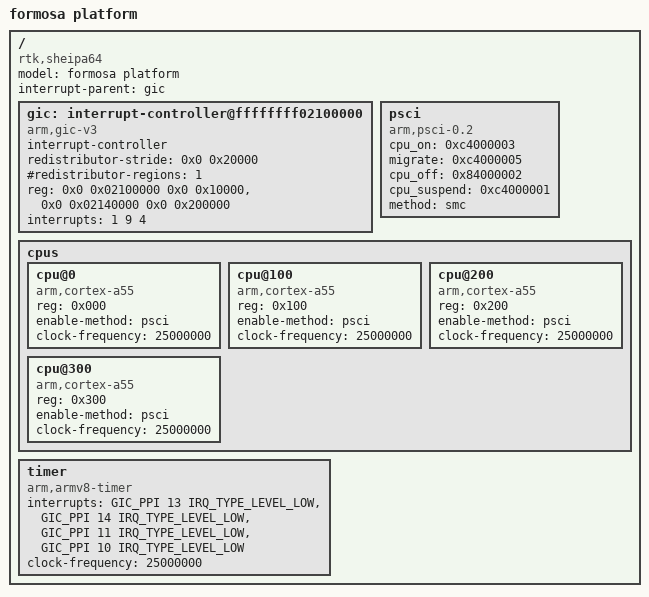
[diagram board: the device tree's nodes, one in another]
/*
 * Realtek Semiconductor Corp.
 *
 * Sheipa platform for AArch64
 *
 * Johnson Yu (jsonyu@realtek.com)
 * Jul. 20, 2017
 */

/dts-v1/;

#include <dt-bindings/interrupt-controller/arm-gic.h>
#include "sheipa64.dtsi"

/ {
	model = "formosa platform";
	compatible = "rtk,sheipa64", "rtk,formosa64";
	interrupt-parent = <&gic>;
	#address-cells = <2>;
	#size-cells = <2>;

        gic: interrupt-controller@ffffffff02100000 {
		compatible = "arm,gic-v3";
		#interrupt-cells = <3>;
		#address-cells = <2>;
		#size-cells = <2>;
		interrupt-controller;
		redistributor-stride = <0x0 0x20000>;
		#redistributor-regions = <1>;
		reg = <0x0 0x02100000 0x0 0x10000>,       /* GICD */
		      <0x0 0x02140000 0x0 0x200000>;      /* GICR */
		interrupts = <1 9 4>;
	};

	psci {
		cpu_on = <0xc4000003>;
		migrate = <0xc4000005>;
		cpu_off = <0x84000002>;
		cpu_suspend = <0xc4000001>;
		method = "smc";
		compatible = "arm,psci-0.2", "arm,psci";
	};

	cpus {
		#size-cells = <0>;
		#address-cells = <1>;

		cpu@0 {
			reg = <0x000>;
			compatible = "arm,cortex-a55";
			device_type = "cpu";
			enable-method = "psci";
			clock-frequency = <25000000>;
		};
		cpu@100 {
			reg = <0x100>;
			compatible = "arm,cortex-a55";
			device_type = "cpu";
			enable-method = "psci";
			clock-frequency = <25000000>;
		};
		cpu@200 {
			reg = <0x200>;
			compatible = "arm,cortex-a55";
			device_type = "notcpu";
			enable-method = "psci";
			clock-frequency = <25000000>;
		};
		cpu@300 {
			reg = <0x300>;
			compatible = "arm,cortex-a55";
			device_type = "notcpu";
			enable-method = "psci";
			clock-frequency = <25000000>;
		};
	};

	timer {
		interrupts = <GIC_PPI 13 IRQ_TYPE_LEVEL_LOW>,
			     <GIC_PPI 14 IRQ_TYPE_LEVEL_LOW>,
			     <GIC_PPI 11 IRQ_TYPE_LEVEL_LOW>,
			     <GIC_PPI 10 IRQ_TYPE_LEVEL_LOW>;
		clock-frequency = <25000000>;
		compatible = "arm,armv8-timer", "arm,armv7-timer";
	};
};
